# STM32H730xxQ register map
File version: 1.0
Registers are 32-bit, read-write, reset 0x0 unless marked. A register's access mark holds for its fields unless they carry their own. Offsets are from the block's base; [hi:lo] are bit positions; lines under a group give offsets from that group; {n}, {i} and the like mark numbered series; 'fields as' and 'values as' point back to an identical list.

## ADC3 — Analog to Digital Converter
Base 0x58026000
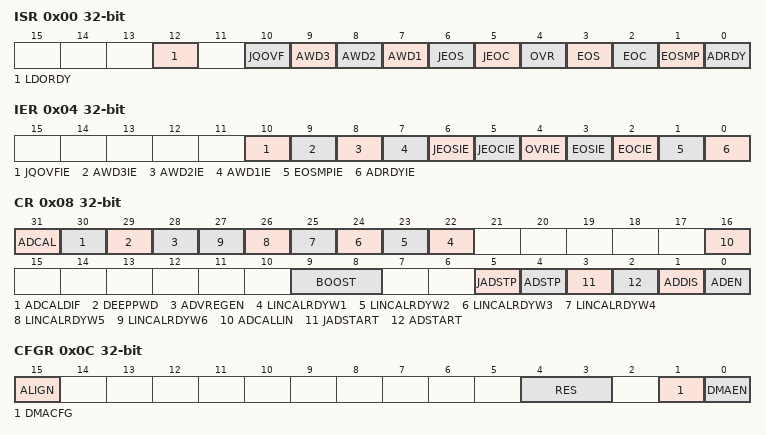
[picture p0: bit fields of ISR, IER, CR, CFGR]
0x00 ISR — ADC Interrupt and Status Register
  [12] LDORDY — ADC LDO output voltage ready bit
  [10] JQOVF — ADC Injected Context Queue Overflow flag
  [9] AWD3 — ADC Analog watchdog 3 flag
  [8] AWD2 — ADC Analog watchdog 2 flag
  [7] AWD1 — ADC Analog watchdog 1 flag
  [6] JEOS — ADC End of Injected sequence of Conversions flag
  [5] JEOC — ADC End of Injected Conversion flag
  [4] OVR — ADC overrun flag
  [3] EOS — ADC End of Regular sequence of Conversions flag
  [2] EOC — ADC End of Regular Conversion flag
  [1] EOSMP — ADC End of Sampling flag
  [0] ADRDY — ADC Ready (ADRDY) flag
0x04 IER — ADC Interrupt Enable Register
  [10] JQOVFIE — ADC Injected Context Queue Overflow interrupt source
  [9] AWD3IE — ADC Analog watchdog 3 interrupt source
  [8] AWD2IE — ADC Analog watchdog 2 interrupt source
  [7] AWD1IE — ADC Analog watchdog 1 interrupt source
  [6] JEOSIE — ADC End of Injected sequence of Conversions interrupt source
  [5] JEOCIE — ADC End of Injected Conversion interrupt source
  [4] OVRIE — ADC overrun interrupt source
  [3] EOSIE — ADC End of Regular sequence of Conversions interrupt source
  [2] EOCIE — ADC End of Regular Conversion interrupt source
  [1] EOSMPIE — ADC End of Sampling interrupt source
  [0] ADRDYIE — ADC Ready (ADRDY) interrupt source
0x08 CR — ADC control register
  [31] ADCAL — ADC Calibration
  [30] ADCALDIF — ADC Differential Mode for calibration
  [29] DEEPPWD — ADC Deep power down Enable
  [28] ADVREGEN — ADC Voltage regulator Enable
  [n+21] LINCALRDYW{n} (n=1..6) — ADC Linearity calibration ready Word {n}
  [16] ADCALLIN — ADC Linearity calibration
  [9:8] BOOST — ADC Boost Mode configuration
  [5] JADSTP — ADC Stop of injected conversion
  [4] ADSTP — ADC Stop of Regular conversion
  [3] JADSTART — ADC Start of injected conversion
  [2] ADSTART — ADC Start of Regular conversion
  [1] ADDIS — ADC Disable command
  [0] ADEN — ADC Enable control
0x0C CFGR — ADC Configuration register
  [15] ALIGN — ADC data alignment
  [4:3] RES — ADC data resolution
  [1] DMACFG — ADC DMA transfer configuration
  [0] DMAEN — ADC DMA transfer enable
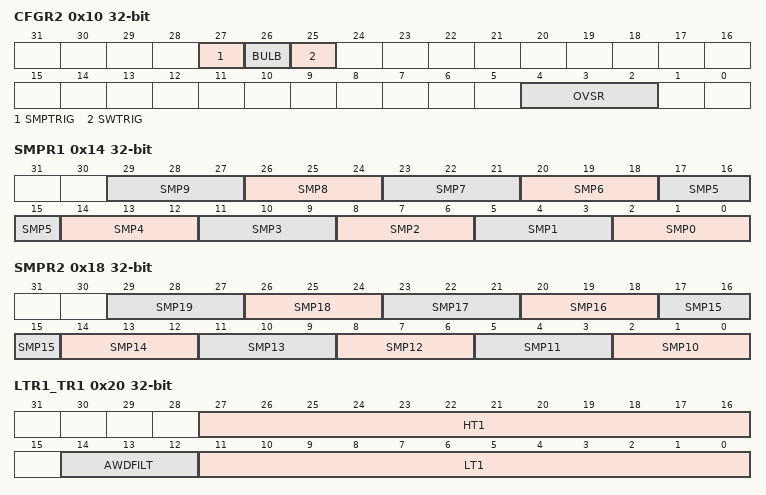
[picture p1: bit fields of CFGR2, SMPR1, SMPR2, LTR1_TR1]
0x10 CFGR2 — ADC Configuration register 2
  [27] SMPTRIG — ADC Sample Time Control Trigger mode
  [26] BULB — ADC Bulb sampling mode
  [25] SWTRIG — ADC Software Trigger Bit for Sample time control trigger mode
  [4:2] OVSR — ADC oversampling ratio
0x14 SMPR1 — ADC sample time register 1
  [3n+2:3n] SMP{n} (n=0..9) — ADC Channel {n} Sampling time selection
0x18 SMPR2 — ADC sample time register 2
  [3n-28:3n-30] SMP{n} (n=10..19) — ADC Channel {n} Sampling time selection
0x1C PCSEL_RES0 — Reserved for ADC3, ADC1/2 pre-channel selection
  [19:0] PCSEL — ADC pre channel selection
0x20 LTR1_TR1 — ADC watchdog Lower threshold register 1
  [27:16] HT1 — ADC analog watchdog 1 threshold high
  [14:12] AWDFILT — ADC analog watchdog filtering parameter
  [11:0] LT1 — ADC analog watchdog 1 threshold low
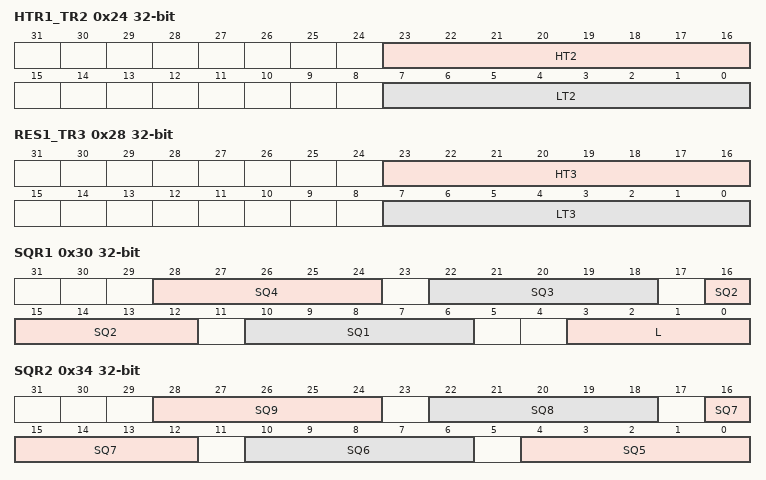
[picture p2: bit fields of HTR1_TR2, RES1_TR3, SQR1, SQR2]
0x24 HTR1_TR2 — ADC watchdog higher threshold register 1
  [23:16] HT2 — ADC analog watchdog 2 threshold high
  [7:0] LT2 — ADC analog watchdog 2 threshold low
0x28 RES1_TR3 — Reserved for ADC1/2, ADC3 threshold register
  [23:16] HT3 — ADC analog watchdog 3 threshold high
  [7:0] LT3 — ADC analog watchdog 3 threshold low
0x30 SQR1 — ADC regular sequence register 1
  [28:24] SQ4 — ADC 4th conversion in regular sequence
  [22:18] SQ3 — ADC 3rd conversion in regular sequence
  [16:12] SQ2 — ADC 2nd conversion in regular sequence
  [10:6] SQ1 — ADC 1st conversion in regular sequence
  [3:0] L — ADC regular channel sequence length
    0=DISABLE (ADC group regular sequencer disable (equivalent to sequencer of 1 rank: ADC conversion on only 1 channel)); {v}=ENABLE_{v+1}RANKS (ADC group regular sequencer enable with {v+1} ranks in the sequence) (v=1..15)
0x34 SQR2 — ADC regular sequence register 2
  [6n-26:6n-30] SQ{n} (n=5..9) — ADC {n}th conversion in regular sequence
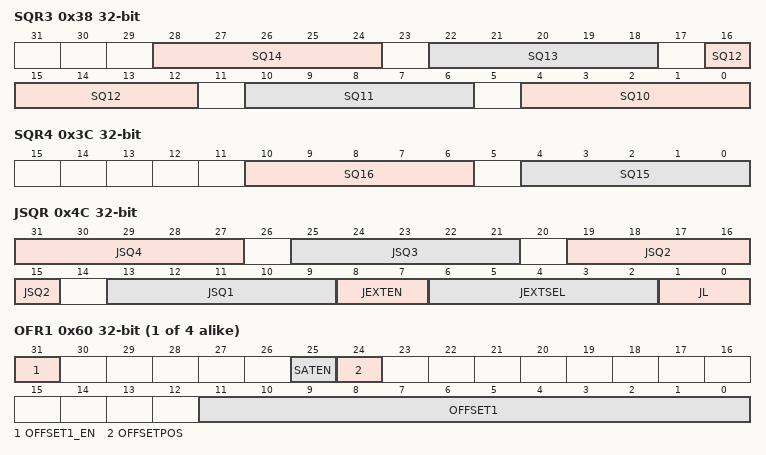
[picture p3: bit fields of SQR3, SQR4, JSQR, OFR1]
0x38 SQR3 — ADC regular sequence register 3
  [6n-56:6n-60] SQ{n} (n=10..14) — ADC {n}th conversion in regular sequence
0x3C SQR4 — ADC regular sequence register 4
  [10:6] SQ16 — ADC 16th conversion in regular sequence
  [4:0] SQ15 — ADC 15th conversion in regular sequence
0x40 DR — ADC regular data register
  [31:0] RDATA — ADC regular Data converted
0x4C JSQR — ADC injected sequence register
  [31:27] JSQ4 — ADC 4th conversion in injected sequence
  [25:21] JSQ3 — ADC 3rd conversion in injected sequence
  [19:15] JSQ2 — ADC 2nd conversion in injected sequence
  [13:9] JSQ1 — ADC 1st conversion in injected sequence
  [8:7] JEXTEN — ADC external trigger enable and polarity selection for injected channels
    1=RISING (ADC group injected conversion trigger polarity set to rising edge); 2=FALLING (ADC group injected conversion trigger polarity set to falling edge); 3=RISINGFALLING (ADC group injected conversion trigger polarity set to both rising and falling edges)
  [6:2] JEXTSEL — ADC external trigger selection for injected group
  [1:0] JL — ADC injected channel sequence length
    0=DISABLE (ADC group injected sequencer disable (equivalent to sequencer of 1 rank: ADC conversion on only 1 channel)); 1=ENABLE_2RANKS (ADC group injected sequencer enable with 2 ranks in the sequence); 2=ENABLE_3RANKS (ADC group injected sequencer enable with 3 ranks in the sequence); 3=ENABLE_4RANKS (ADC group injected sequencer enable with 4 ranks in the sequence)
{0x5C+4i} OFR{i} (i=1..4) — ADC
  [31] OFFSET{i}_EN — ADC offset number {i} enable
  [25] SATEN — ADC offset number {i} saturation enable
  [24] OFFSETPOS — ADC offset number {i} positive
  [11:0] OFFSET{i} — ADC data offset {i} for channel programmed into bits OFFSET1_CH[4:0]
{0x7C+4i} JDR{i} (i=1..4) — ADC injected data register {i}
  [31:0] JDATA — ADC Injected DATA
0xA0 AWD2CR — ADC Analog Watchdog 2 Configuration Register
  [18:0] AWD2CH — ADC Analog watchdog 2 channel selection
0xA4 AWD3CR — ADC Analog Watchdog 3 Configuration Register
  [18:0] AWD3CH — ADC Analog watchdog 3 channel selection
0xB0 LTR2_DIFSEL — ADC watchdog Lower threshold register 2, Difsel for ADC3
  [25:0] LT — ADC Analog watchdog 1, 2 and 3 lower threshold
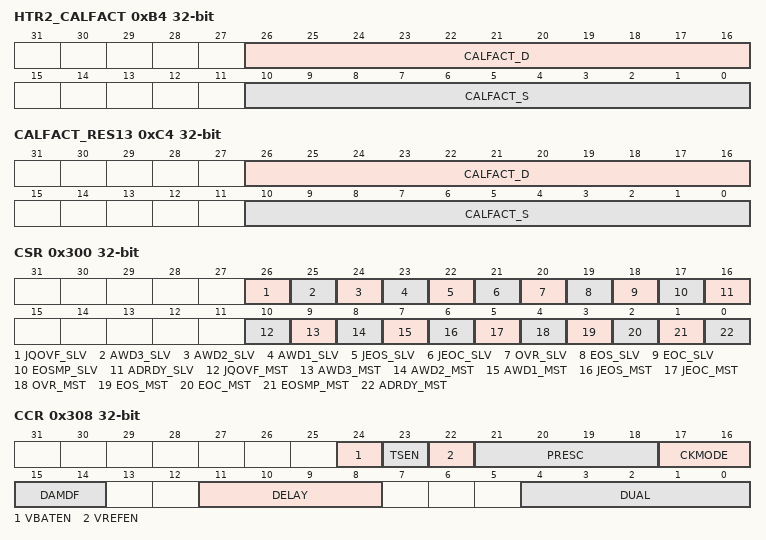
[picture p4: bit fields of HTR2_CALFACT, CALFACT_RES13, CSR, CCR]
0xB4 HTR2_CALFACT — ADC watchdog Higher threshold register 2, Calfact for ADC3
  [26:16] CALFACT_D — ADC calibration factors in differential mode
  [10:0] CALFACT_S — ADC calibration factors in single-ended mode
0xB8 LTR3_RES10 — ADC watchdog Lower threshold register 3, specific ADC1/2
  [25:0] LT — ADC Analog watchdog 1, 2 and 3 lower threshold
0xBC HTR3_RES11 — ADC watchdog Higher threshold register 3, specific ADC1/2
  [25:0] HT — ADC Analog watchdog 1,2 and 3 higher threshold
0xC0 DIFSEL_RES12 — ADC Differential Mode Selection Register specific ADC1/2
  [19:0] DIFSEL — ADC differential modes for channels 1 to 18
0xC4 CALFACT_RES13 — ADC Calibration Factors specific ADC1/2
  fields as HTR2_CALFACT
0xC8 CALFACT2_RES14 — ADC Linearity Calibration Factors specific ADC1/2
  [29:0] LINCALFACT — ADC Linearity calibration factors
0x300 CSR — ADC Common status register
  [26] JQOVF_SLV — Injected context queue overflow flag of the slave ADC
  [25] AWD3_SLV — Analog watchdog 3 flag of the slave ADC
  [24] AWD2_SLV — Analog watchdog 2 flag of the slave ADC
  [23] AWD1_SLV — Analog watchdog 1 flag of the slave ADC
  [22] JEOS_SLV — End of injected sequence flag of the slave ADC
  [21] JEOC_SLV — End of injected conversion of the slave ADC
  [20] OVR_SLV — Overrun flag of the slave ADC
  [19] EOS_SLV — End of regular sequence flag of the slave ADC
  [18] EOC_SLV — End of regular conversion of the slave ADC
  [17] EOSMP_SLV — End of sampling phase flag of the slave ADC
  [16] ADRDY_SLV — Slave ADC ready
  [10] JQOVF_MST — Injected context queue overflow flag of the master ADC
  [9] AWD3_MST — Analog watchdog 3 flag of the master ADC
  [8] AWD2_MST — Analog watchdog 2 flag of the master ADC
  [7] AWD1_MST — Analog watchdog 1 flag of the master ADC
  [6] JEOS_MST — End of injected sequence flag of the master ADC
  [5] JEOC_MST — End of injected conversion of the master ADC
  [4] OVR_MST — Overrun flag of the master ADC
  [3] EOS_MST — End of regular sequence flag of the master ADC
  [2] EOC_MST — End of regular conversion of the master ADC
  [1] EOSMP_MST — End of sampling phase flag of the master ADC
  [0] ADRDY_MST — Master ADC ready
0x308 CCR — ADC common control register
  [24] VBATEN — VBAT enable
  [23] TSEN — Temperature sensor enable
  [22] VREFEN — VREFINT enable
  [21:18] PRESC — ADC prescaler
  [17:16] CKMODE — ADC clock mode
  [15:14] DAMDF — Dual ADC mode Data format
    0=EACH_ADC (ADC multimode group regular conversions are transferred by DMA: each ADC uses its own DMA channel, with its individual DMA transfer settings); 2=RES_32_10B (ADC multimode group regular conversions are transferred by DMA, one DMA channel for both ADC (DMA of ADC master). Setting for ADC resolution of 32 (16x2) down to 10 bits); 3=RES_8B (ADC multimode group regular conversions are transferred by DMA, one DMA channel for both ADC (DMA of ADC master). Setting for ADC resolution of 8 bits)
  [11:8] DELAY — Delay between 2 sampling phases
    0=DELAY_1CYCLE_5 (ADC multimode delay between two sampling phases: 1.5 ADC clock cycle for all resolution); 1=DELAY_2CYCLES_5 (ADC multimode delay between two sampling phases: 2.5 ADC clock cycles for all resolution); 2=DELAY_3CYCLES_5 (ADC multimode delay between two sampling phases: 3.5 ADC clock cycles for all resolution); 3=DELAY_4CYCLES_5 (ADC multimode delay between two sampling phases: 4.5 ADC clock cycles for 16, 14, 12 or 10 bits resolution); 7=DELAY_4CYCLES_5_8_BITS (ADC multimode delay between two sampling phases: 4.5 ADC clock cycles for 8 bits resolution); 4=DELAY_5CYCLES_5 (ADC multimode delay between two sampling phases: 5.5 ADC clock cycles for 16, 14, 12 bits resolution); 8=DELAY_6CYCLES (ADC multimode delay between two sampling phases: 6 ADC clock cycles for 10 or 8 bits resolution); 5=DELAY_6CYCLES_5 (ADC multimode delay between two sampling phases: 6.5 ADC clock cycles for 16 or 14 bits resolution)
  [4:0] DUAL — Dual ADC mode selection
    0=INDEPENDENT (ADC dual mode disabled (ADC independent mode)); 6=DUAL_REG_SIMULT (ADC dual mode enabled: group regular simultaneous); 7=DUAL_REG_INTERL (ADC dual mode enabled: Combined group regular interleaved); 5=DUAL_INJ_SIMULT (ADC dual mode enabled: group injected simultaneous); 9=DUAL_INJ_ALTERN (ADC dual mode enabled: group injected alternate trigger. Works only with external triggers (not internal SW start)); 1=DUAL_REG_SIM_INJ_SIM (ADC dual mode enabled: Combined group regular simultaneous + group injected simultaneous); 2=DUAL_REG_SIM_INJ_ALT (ADC dual mode enabled: Combined group regular simultaneous + group injected alternate trigger); 3=DUAL_REG_INT_INJ_SIM (ADC dual mode enabled: Combined group regular interleaved + group injected simultaneous)
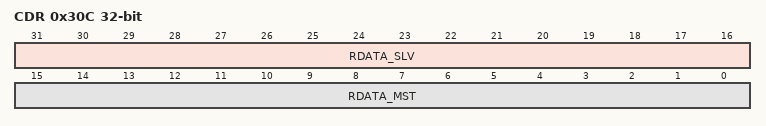
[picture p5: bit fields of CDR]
0x30C CDR — ADC common regular data register for dual
  [31:16] RDATA_SLV — ADC multimode slave group regular conversion data
  [15:0] RDATA_MST — ADC multimode master group regular conversion data
0x310 CDR2 — ADC common regular data register for 32-bit dual mode
  [31:0] RDATA_ALT — Regular data of the master/slave alternated ADCs
